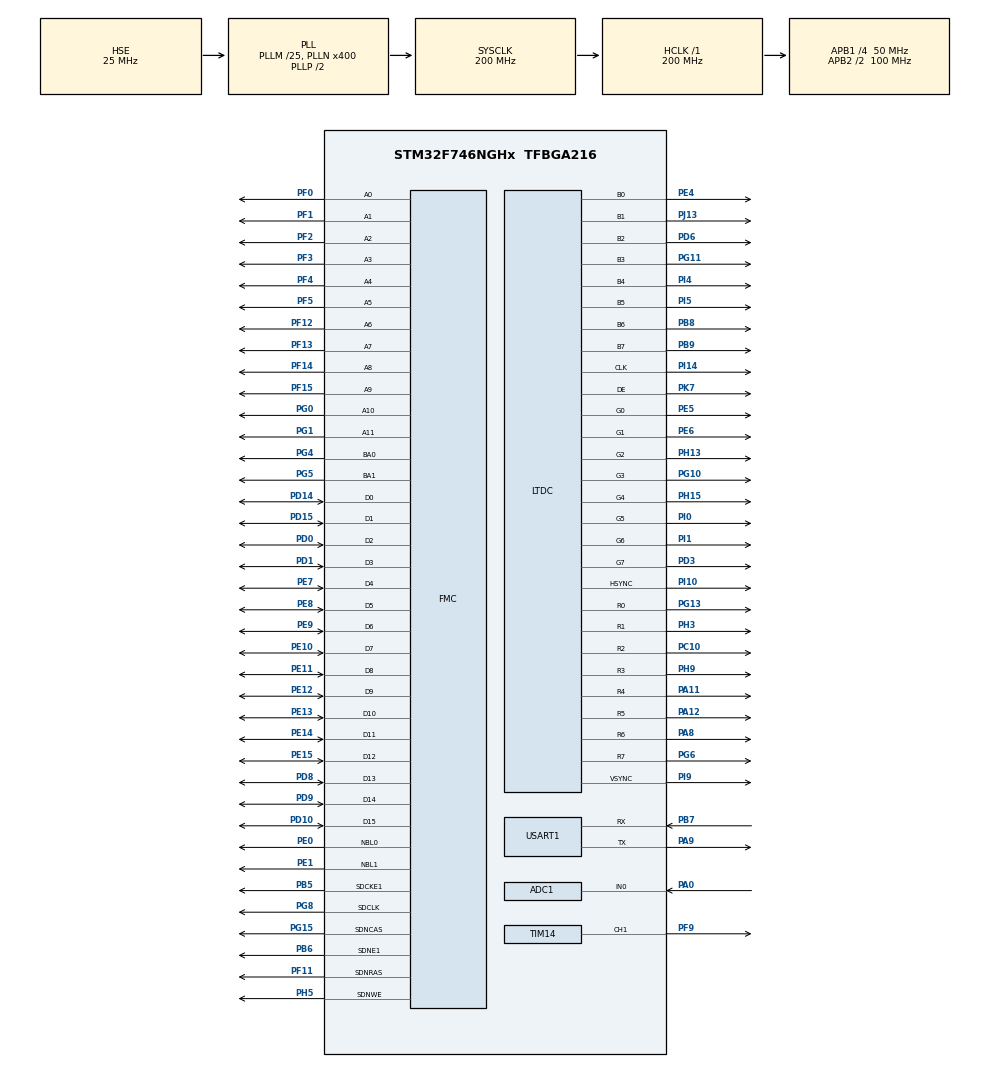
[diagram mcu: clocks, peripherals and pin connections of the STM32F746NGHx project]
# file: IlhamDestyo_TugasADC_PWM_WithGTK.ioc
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ADC1.Channel-1\#ChannelRegularConversion=ADC_CHANNEL_0
ADC1.ContinuousConvMode=ENABLE
ADC1.InjNumberOfConversion=0
ADC1.NbrOfConversionFlag=1
ADC1.Rank-1\#ChannelRegularConversion=1
ADC1.Resolution=ADC_RESOLUTION_12B
ADC1.SamplingTime-1\#ChannelRegularConversion=ADC_SAMPLETIME_144CYCLES
ADC1.master=1
CORTEX_M7.CPU_DCache=Enabled
CORTEX_M7.CPU_ICache=Enabled
FMC.WriteProtection1=FMC_SDRAM_WRITE_PROTECTION_DISABLE
FREERTOS.Tasks01=ADC_Task,3,128,StartADC,Default,NULL,Dynamic,NULL,NULL;PWM_Task,0,128,StartPWM,Default,NULL,Dynamic,NULL,NULL
FREERTOS.configUSE_NEWLIB_REENTRANT=1
LTDC.ActiveH=272
LTDC.ActiveW=480
Mcu.Family=STM32F7
Mcu.Name=STM32F746NGHx
Mcu.Package=TFBGA216
NVIC.LTDC_IRQn=true\:5\:0\:false\:false\:true\:true\:true\:true\:true
NVIC.PriorityGroup=NVIC_PRIORITYGROUP_4
NVIC.RCC_IRQn=true\:5\:0\:false\:false\:true\:true\:true\:false\:true
PA0/WKUP.Signal=ADCx_IN0
PA11.Mode=RGB888
PA11.Signal=LTDC_R4
PA12.Mode=RGB888
PA12.Signal=LTDC_R5
PA13.Mode=Serial_Wire
PA13.Signal=SYS_JTMS-SWDIO
PA14.Mode=Serial_Wire
PA14.Signal=SYS_JTCK-SWCLK
PA8.Mode=RGB888
PA8.Signal=LTDC_R6
PA9.Mode=Asynchronous
PA9.Signal=USART1_TX
PB5.Mode=SdramChipSelect2_1
PB5.Signal=FMC_SDCKE1
PB6.Mode=SdramChipSelect2_1
PB6.Signal=FMC_SDNE1
PB7.Mode=Asynchronous
PB7.Signal=USART1_RX
PB8.Mode=RGB888
PB8.Signal=LTDC_B6
PB9.Mode=RGB888
PB9.Signal=LTDC_B7
PC10.Mode=RGB888
PC10.Signal=LTDC_R2
PD0.Signal=FMC_D2_DA2
PD1.Signal=FMC_D3_DA3
PD10.Signal=FMC_D15_DA15
PD14.Signal=FMC_D0_DA0
PD15.Signal=FMC_D1_DA1
PD3.Mode=RGB888
PD3.Signal=LTDC_G7
PD6.Mode=RGB888
PD6.Signal=LTDC_B2
PD8.Signal=FMC_D13_DA13
PD9.Signal=FMC_D14_DA14
PE0.Signal=FMC_NBL0
PE1.Signal=FMC_NBL1
PE10.Signal=FMC_D7_DA7
PE11.Signal=FMC_D8_DA8
PE12.Signal=FMC_D9_DA9
PE13.Signal=FMC_D10_DA10
PE14.Signal=FMC_D11_DA11
PE15.Signal=FMC_D12_DA12
PE4.Mode=RGB888
PE4.Signal=LTDC_B0
PE5.Mode=RGB888
PE5.Signal=LTDC_G0
PE6.Mode=RGB888
PE6.Signal=LTDC_G1
PE7.Signal=FMC_D4_DA4
PE8.Signal=FMC_D5_DA5
PE9.Signal=FMC_D6_DA6
PF0.Signal=FMC_A0
PF1.Signal=FMC_A1
PF11.Signal=FMC_SDNRAS
PF12.Signal=FMC_A6
PF13.Signal=FMC_A7
PF14.Signal=FMC_A8
PF15.Signal=FMC_A9
PF2.Signal=FMC_A2
PF3.Signal=FMC_A3
PF4.Signal=FMC_A4
PF5.Signal=FMC_A5
PF9.Signal=S_TIM14_CH1
PG0.Signal=FMC_A10
PG1.Signal=FMC_A11
PG10.Mode=RGB888
PG10.Signal=LTDC_G3
PG11.Mode=RGB888
PG11.Signal=LTDC_B3
PG13.Mode=RGB888
PG13.Signal=LTDC_R0
PG15.Signal=FMC_SDNCAS
PG4.Signal=FMC_A14_BA0
PG5.Signal=FMC_A15_BA1
PG6.Mode=RGB888
PG6.Signal=LTDC_R7
PG8.Signal=FMC_SDCLK
PH0/OSC_IN.Mode=HSE-External-Oscillator
PH0/OSC_IN.Signal=RCC_OSC_IN
PH1/OSC_OUT.Mode=HSE-External-Oscillator
PH1/OSC_OUT.Signal=RCC_OSC_OUT
PH13.Mode=RGB888
PH13.Signal=LTDC_G2
PH15.Mode=RGB888
PH15.Signal=LTDC_G4
PH3.Mode=RGB888
PH3.Signal=LTDC_R1
PH5.Signal=FMC_SDNWE
PH9.Mode=RGB888
PH9.Signal=LTDC_R3
PI0.Mode=RGB888
PI0.Signal=LTDC_G5
PI1.Mode=RGB888
PI1.Signal=LTDC_G6
PI10.Mode=RGB888
PI10.Signal=LTDC_HSYNC
PI14.Mode=RGB888
PI14.Signal=LTDC_CLK
PI4.Mode=RGB888
PI4.Signal=LTDC_B4
PI5.Mode=RGB888
PI5.Signal=LTDC_B5
PI9.Mode=RGB888
PI9.Signal=LTDC_VSYNC
PJ13.Mode=RGB888
PJ13.Signal=LTDC_B1
PK7.Mode=RGB888
PK7.Signal=LTDC_DE
ProjectManager.HeapSize=0x200
ProjectManager.StackSize=0x400
ProjectManager.TargetToolchain=STM32CubeIDE
RCC.AHBFreq_Value=200000000
RCC.APB1CLKDivider=RCC_HCLK_DIV4
RCC.APB1Freq_Value=50000000
RCC.APB1TimFreq_Value=100000000
RCC.APB2CLKDivider=RCC_HCLK_DIV2
RCC.APB2Freq_Value=100000000
RCC.APB2TimFreq_Value=200000000
RCC.CortexFreq_Value=200000000
RCC.HCLKFreq_Value=200000000
RCC.HSE_VALUE=25000000
RCC.HSI_VALUE=16000000
RCC.LSE_VALUE=32768
RCC.PLL48CLockSelection=RCC_CLK48SOURCE_PLLSAIP
RCC.PLLI2SN=100
RCC.PLLM=25
RCC.PLLN=400
RCC.PLLQ=9
RCC.PLLSAIN=384
RCC.PLLSAIP=RCC_PLLSAIP_DIV8
RCC.PLLSAIR=5
RCC.PLLSAIRDiv=RCC_PLLSAIDIVR_8
RCC.PLLSourceVirtual=RCC_PLLSOURCE_HSE
RCC.SDMMCClockSelection=RCC_SDMMC1CLKSOURCE_CLK48
RCC.SYSCLKFreq_VALUE=200000000
RCC.SYSCLKSource=RCC_SYSCLKSOURCE_PLLCLK
RCC.USBFreq_Value=48000000
RCC.VCOOutputFreq_Value=400000000
SH.ADCx_IN0.0=ADC1_IN0,IN0
SH.FMC_A0.0=FMC_A0,12b-sda1
SH.FMC_A1.0=FMC_A1,12b-sda1
SH.FMC_A10.0=FMC_A10,12b-sda1
SH.FMC_A11.0=FMC_A11,12b-sda1
SH.FMC_A14_BA0.0=FMC_BA0,FourSdramBanks1
SH.FMC_A15_BA1.0=FMC_BA1,FourSdramBanks1
SH.FMC_A2.0=FMC_A2,12b-sda1
SH.FMC_A3.0=FMC_A3,12b-sda1
SH.FMC_A4.0=FMC_A4,12b-sda1
SH.FMC_A5.0=FMC_A5,12b-sda1
SH.FMC_A6.0=FMC_A6,12b-sda1
SH.FMC_A7.0=FMC_A7,12b-sda1
SH.FMC_A8.0=FMC_A8,12b-sda1
SH.FMC_A9.0=FMC_A9,12b-sda1
SH.FMC_D0_DA0.0=FMC_D0,sd-16b-d1
SH.FMC_D10_DA10.0=FMC_D10,sd-16b-d1
SH.FMC_D11_DA11.0=FMC_D11,sd-16b-d1
SH.FMC_D12_DA12.0=FMC_D12,sd-16b-d1
SH.FMC_D13_DA13.0=FMC_D13,sd-16b-d1
SH.FMC_D14_DA14.0=FMC_D14,sd-16b-d1
SH.FMC_D15_DA15.0=FMC_D15,sd-16b-d1
SH.FMC_D1_DA1.0=FMC_D1,sd-16b-d1
SH.FMC_D2_DA2.0=FMC_D2,sd-16b-d1
SH.FMC_D3_DA3.0=FMC_D3,sd-16b-d1
SH.FMC_D4_DA4.0=FMC_D4,sd-16b-d1
SH.FMC_D5_DA5.0=FMC_D5,sd-16b-d1
SH.FMC_D6_DA6.0=FMC_D6,sd-16b-d1
SH.FMC_D7_DA7.0=FMC_D7,sd-16b-d1
SH.FMC_D8_DA8.0=FMC_D8,sd-16b-d1
SH.FMC_D9_DA9.0=FMC_D9,sd-16b-d1
SH.FMC_NBL0.0=FMC_NBL0,Sd2ByteEnable1
SH.FMC_NBL1.0=FMC_NBL1,Sd2ByteEnable1
SH.FMC_SDCLK.0=FMC_SDCLK,12b-sda1
SH.FMC_SDNCAS.0=FMC_SDNCAS,12b-sda1
SH.FMC_SDNRAS.0=FMC_SDNRAS,12b-sda1
SH.FMC_SDNWE.0=FMC_SDNWE,12b-sda1
SH.S_TIM14_CH1.0=TIM14_CH1,PWM Generation1 CH1
TIM14.Channel=TIM_CHANNEL_1
TIM14.Period=1000
TIM14.Prescaler=840-1
USART1.VirtualMode-Asynchronous=VM_ASYNC
VP_CRC_VS_CRC.Mode=CRC_Activate
VP_DMA2D_VS_DMA2D.Mode=DMA2D_Activate
VP_FREERTOS_VS_CMSIS_V1.Mode=CMSIS_V1
VP_TIM14_VS_ClockSourceINT.Mode=Enable_Timer
board=STM32F746G-DISCO

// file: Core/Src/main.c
/* USER CODE BEGIN Header */
/**
  ******************************************************************************
  * @file           : main.c
  * @brief          : Main program body
  ******************************************************************************
  * @attention
  *
  * Copyright (c) 2022 STMicroelectronics.
  * All rights reserved.
  *
  * This software is licensed under terms that can be found in the LICENSE file
  * in the root directory of this software component.
  * If no LICENSE file comes with this software, it is provided AS-IS.
  *
  ******************************************************************************
  */
/* USER CODE END Header */
#include "main.h"
#include "cmsis_os.h"

/* USER CODE BEGIN Includes */
#include <stdio.h>
#include <stdlib.h>
#include <string.h>
#include <ctype.h>
/* USER CODE END Includes */

 ADC_HandleTypeDef hadc1;

CRC_HandleTypeDef hcrc;

DMA2D_HandleTypeDef hdma2d;

LTDC_HandleTypeDef hltdc;

TIM_HandleTypeDef htim14;

UART_HandleTypeDef huart1;

SDRAM_HandleTypeDef hsdram1;

osThreadId ADC_TaskHandle;
osThreadId PWM_TaskHandle;
/* USER CODE BEGIN PV */
int adcValue;
HAL_StatusTypeDef ret;
int PWM;
char *adc, *datapwm;
ADC_ChannelConfTypeDef sConfigPrivate = {0};

uint8_t Rx_data[64];
uint8_t Tx_data[64];
uint8_t buffer[64];
/* USER CODE END PV */

void SystemClock_Config(void);
static void MX_GPIO_Init(void);
static void MX_CRC_Init(void);
static void MX_DMA2D_Init(void);
static void MX_FMC_Init(void);
static void MX_LTDC_Init(void);
static void MX_USART1_UART_Init(void);
static void MX_ADC1_Init(void);
static void MX_TIM14_Init(void);
void StartADC(void const * argument);
void StartPWM(void const * argument);

/* USER CODE BEGIN PFP */
char *IntToStr(int x);
/* USER CODE END PFP */

int main(void)
{

  /* Enable I-Cache---------------------------------------------------------*/
  SCB_EnableICache();

  /* Enable D-Cache---------------------------------------------------------*/
  SCB_EnableDCache();

  /* MCU Configuration--------------------------------------------------------*/

  /* Reset of all peripherals, Initializes the Flash interface and the Systick. */
  HAL_Init();

  /* Configure the system clock */
  SystemClock_Config();

  /* Initialize all configured peripherals */
  MX_GPIO_Init();
  MX_CRC_Init();
  MX_DMA2D_Init();
  MX_FMC_Init();
  MX_LTDC_Init();
  MX_USART1_UART_Init();
  MX_ADC1_Init();
  MX_TIM14_Init();
  /* USER CODE BEGIN 2 */
  HAL_TIM_PWM_Start(&htim14, TIM_CHANNEL_1); // set enable start TIM4 CH 1

  BSP_SDRAM_Init(); /* Initializes the SDRAM device */
 __HAL_RCC_CRC_CLK_ENABLE(); /* Enable the CRC Module */
 //
 BSP_TS_Init(480, 272);

 BSP_LCD_Init();	// inisialisasi LCD
 BSP_LCD_LayerDefaultInit(LTDC_ACTIVE_LAYER, LCD_FB_START_ADDRESS); // inisialisasi layer
 BSP_LCD_SelectLayer(LTDC_ACTIVE_LAYER); // set layer

 BSP_LCD_Clear(LCD_COLOR_DARKGREEN); // set clear lcd color black
 BSP_LCD_SetFont(&LCD_DEFAULT_FONT); // set font lcd
 BSP_LCD_SetTextColor(LCD_COLOR_BROWN);
  /* USER CODE END 2 */

  /* Create the thread(s) */
  /* definition and creation of ADC_Task */
  osThreadDef(ADC_Task, StartADC, osPriorityRealtime, 0, 128);
  ADC_TaskHandle = osThreadCreate(osThread(ADC_Task), NULL);

  /* definition and creation of PWM_Task */
  osThreadDef(PWM_Task, StartPWM, osPriorityNormal, 0, 128);
  PWM_TaskHandle = osThreadCreate(osThread(PWM_Task), NULL);

  /* Start scheduler */
  osKernelStart();

  /* We should never get here as control is now taken by the scheduler */
  /* Infinite loop */
  while (1)
  {

  }
}

void SystemClock_Config(void)
{
  RCC_OscInitTypeDef RCC_OscInitStruct = {0};
  RCC_ClkInitTypeDef RCC_ClkInitStruct = {0};

  /** Configure the main internal regulator output voltage
  */
  __HAL_RCC_PWR_CLK_ENABLE();
  __HAL_PWR_VOLTAGESCALING_CONFIG(PWR_REGULATOR_VOLTAGE_SCALE1);

  /** Initializes the RCC Oscillators according to the specified parameters
  * in the RCC_OscInitTypeDef structure.
  */
  RCC_OscInitStruct.OscillatorType = RCC_OSCILLATORTYPE_HSE;
  RCC_OscInitStruct.HSEState = RCC_HSE_ON;
  RCC_OscInitStruct.PLL.PLLState = RCC_PLL_ON;
  RCC_OscInitStruct.PLL.PLLSource = RCC_PLLSOURCE_HSE;
  RCC_OscInitStruct.PLL.PLLM = 25;
  RCC_OscInitStruct.PLL.PLLN = 400;
  RCC_OscInitStruct.PLL.PLLP = RCC_PLLP_DIV2;
  RCC_OscInitStruct.PLL.PLLQ = 9;
  if (HAL_RCC_OscConfig(&RCC_OscInitStruct) != HAL_OK)
  {
    Error_Handler();
  }

  /** Activate the Over-Drive mode
  */
  if (HAL_PWREx_EnableOverDrive() != HAL_OK)
  {
    Error_Handler();
  }

  /** Initializes the CPU, AHB and APB buses clocks
  */
  RCC_ClkInitStruct.ClockType = RCC_CLOCKTYPE_HCLK|RCC_CLOCKTYPE_SYSCLK
                              |RCC_CLOCKTYPE_PCLK1|RCC_CLOCKTYPE_PCLK2;
  RCC_ClkInitStruct.SYSCLKSource = RCC_SYSCLKSOURCE_PLLCLK;
  RCC_ClkInitStruct.AHBCLKDivider = RCC_SYSCLK_DIV1;
  RCC_ClkInitStruct.APB1CLKDivider = RCC_HCLK_DIV4;
  RCC_ClkInitStruct.APB2CLKDivider = RCC_HCLK_DIV2;

  if (HAL_RCC_ClockConfig(&RCC_ClkInitStruct, FLASH_LATENCY_6) != HAL_OK)
  {
    Error_Handler();
  }
}

static void MX_ADC1_Init(void)
{

  ADC_ChannelConfTypeDef sConfig = {0};

  /** Configure the global features of the ADC (Clock, Resolution, Data Alignment and number of conversion)
  */
  hadc1.Instance = ADC1;
  hadc1.Init.ClockPrescaler = ADC_CLOCK_SYNC_PCLK_DIV4;
  hadc1.Init.Resolution = ADC_RESOLUTION_12B;
  hadc1.Init.ScanConvMode = ADC_SCAN_DISABLE;
  hadc1.Init.ContinuousConvMode = ENABLE;
  hadc1.Init.DiscontinuousConvMode = DISABLE;
  hadc1.Init.ExternalTrigConvEdge = ADC_EXTERNALTRIGCONVEDGE_NONE;
  hadc1.Init.ExternalTrigConv = ADC_SOFTWARE_START;
  hadc1.Init.DataAlign = ADC_DATAALIGN_RIGHT;
  hadc1.Init.NbrOfConversion = 1;
  hadc1.Init.DMAContinuousRequests = DISABLE;
  hadc1.Init.EOCSelection = ADC_EOC_SINGLE_CONV;
  if (HAL_ADC_Init(&hadc1) != HAL_OK)
  {
    Error_Handler();
  }

  /** Configure for the selected ADC regular channel its corresponding rank in the sequencer and its sample time.
  */
  sConfig.Channel = ADC_CHANNEL_0;
  sConfig.Rank = ADC_REGULAR_RANK_1;
  sConfig.SamplingTime = ADC_SAMPLETIME_144CYCLES;
  if (HAL_ADC_ConfigChannel(&hadc1, &sConfig) != HAL_OK)
  {
    Error_Handler();
  }

}

static void MX_CRC_Init(void)
{

  hcrc.Instance = CRC;
  hcrc.Init.DefaultPolynomialUse = DEFAULT_POLYNOMIAL_ENABLE;
  hcrc.Init.DefaultInitValueUse = DEFAULT_INIT_VALUE_ENABLE;
  hcrc.Init.InputDataInversionMode = CRC_INPUTDATA_INVERSION_NONE;
  hcrc.Init.OutputDataInversionMode = CRC_OUTPUTDATA_INVERSION_DISABLE;
  hcrc.InputDataFormat = CRC_INPUTDATA_FORMAT_BYTES;
  if (HAL_CRC_Init(&hcrc) != HAL_OK)
  {
    Error_Handler();
  }

}

static void MX_DMA2D_Init(void)
{

  hdma2d.Instance = DMA2D;
  hdma2d.Init.Mode = DMA2D_M2M;
  hdma2d.Init.ColorMode = DMA2D_OUTPUT_ARGB8888;
  hdma2d.Init.OutputOffset = 0;
  hdma2d.LayerCfg[1].InputOffset = 0;
  hdma2d.LayerCfg[1].InputColorMode = DMA2D_INPUT_ARGB8888;
  hdma2d.LayerCfg[1].AlphaMode = DMA2D_NO_MODIF_ALPHA;
  hdma2d.LayerCfg[1].InputAlpha = 0;
  if (HAL_DMA2D_Init(&hdma2d) != HAL_OK)
  {
    Error_Handler();
  }
  if (HAL_DMA2D_ConfigLayer(&hdma2d, 1) != HAL_OK)
  {
    Error_Handler();
  }

}

static void MX_LTDC_Init(void)
{

  LTDC_LayerCfgTypeDef pLayerCfg = {0};
  LTDC_LayerCfgTypeDef pLayerCfg1 = {0};

  hltdc.Instance = LTDC;
  hltdc.Init.HSPolarity = LTDC_HSPOLARITY_AL;
  hltdc.Init.VSPolarity = LTDC_VSPOLARITY_AL;
  hltdc.Init.DEPolarity = LTDC_DEPOLARITY_AL;
  hltdc.Init.PCPolarity = LTDC_PCPOLARITY_IPC;
  hltdc.Init.HorizontalSync = 7;
  hltdc.Init.VerticalSync = 3;
  hltdc.Init.AccumulatedHBP = 14;
  hltdc.Init.AccumulatedVBP = 5;
  hltdc.Init.AccumulatedActiveW = 494;
  hltdc.Init.AccumulatedActiveH = 277;
  hltdc.Init.TotalWidth = 500;
  hltdc.Init.TotalHeigh = 279;
  hltdc.Init.Backcolor.Blue = 0;
  hltdc.Init.Backcolor.Green = 0;
  hltdc.Init.Backcolor.Red = 0;
  if (HAL_LTDC_Init(&hltdc) != HAL_OK)
  {
    Error_Handler();
  }
  pLayerCfg.WindowX0 = 0;
  pLayerCfg.WindowX1 = 0;
  pLayerCfg.WindowY0 = 0;
  pLayerCfg.WindowY1 = 0;
  pLayerCfg.PixelFormat = LTDC_PIXEL_FORMAT_ARGB8888;
  pLayerCfg.Alpha = 0;
  pLayerCfg.Alpha0 = 0;
  pLayerCfg.BlendingFactor1 = LTDC_BLENDING_FACTOR1_CA;
  pLayerCfg.BlendingFactor2 = LTDC_BLENDING_FACTOR2_CA;
  pLayerCfg.FBStartAdress = 0;
  pLayerCfg.ImageWidth = 0;
  pLayerCfg.ImageHeight = 0;
  pLayerCfg.Backcolor.Blue = 0;
  pLayerCfg.Backcolor.Green = 0;
  pLayerCfg.Backcolor.Red = 0;
  if (HAL_LTDC_ConfigLayer(&hltdc, &pLayerCfg, 0) != HAL_OK)
  {
    Error_Handler();
  }
  pLayerCfg1.WindowX0 = 0;
  pLayerCfg1.WindowX1 = 0;
  pLayerCfg1.WindowY0 = 0;
  pLayerCfg1.WindowY1 = 0;
  pLayerCfg1.PixelFormat = LTDC_PIXEL_FORMAT_ARGB8888;
  pLayerCfg1.Alpha = 0;
  pLayerCfg1.Alpha0 = 0;
  pLayerCfg1.BlendingFactor1 = LTDC_BLENDING_FACTOR1_CA;
  pLayerCfg1.BlendingFactor2 = LTDC_BLENDING_FACTOR2_CA;
  pLayerCfg1.FBStartAdress = 0;
  pLayerCfg1.ImageWidth = 0;
  pLayerCfg1.ImageHeight = 0;
  pLayerCfg1.Backcolor.Blue = 0;
  pLayerCfg1.Backcolor.Green = 0;
  pLayerCfg1.Backcolor.Red = 0;
  if (HAL_LTDC_ConfigLayer(&hltdc, &pLayerCfg1, 1) != HAL_OK)
  {
    Error_Handler();
  }

}

static void MX_TIM14_Init(void)
{

  TIM_OC_InitTypeDef sConfigOC = {0};

  htim14.Instance = TIM14;
  htim14.Init.Prescaler = 840-1;
  htim14.Init.CounterMode = TIM_COUNTERMODE_UP;
  htim14.Init.Period = 1000;
  htim14.Init.ClockDivision = TIM_CLOCKDIVISION_DIV1;
  htim14.Init.AutoReloadPreload = TIM_AUTORELOAD_PRELOAD_DISABLE;
  if (HAL_TIM_Base_Init(&htim14) != HAL_OK)
  {
    Error_Handler();
  }
  if (HAL_TIM_PWM_Init(&htim14) != HAL_OK)
  {
    Error_Handler();
  }
  sConfigOC.OCMode = TIM_OCMODE_PWM1;
  sConfigOC.Pulse = 0;
  sConfigOC.OCPolarity = TIM_OCPOLARITY_HIGH;
  sConfigOC.OCFastMode = TIM_OCFAST_DISABLE;
  if (HAL_TIM_PWM_ConfigChannel(&htim14, &sConfigOC, TIM_CHANNEL_1) != HAL_OK)
  {
    Error_Handler();
  }
  HAL_TIM_MspPostInit(&htim14);

}

static void MX_USART1_UART_Init(void)
{

  huart1.Instance = USART1;
  huart1.Init.BaudRate = 115200;
  huart1.Init.WordLength = UART_WORDLENGTH_8B;
  huart1.Init.StopBits = UART_STOPBITS_1;
  huart1.Init.Parity = UART_PARITY_NONE;
  huart1.Init.Mode = UART_MODE_TX_RX;
  huart1.Init.HwFlowCtl = UART_HWCONTROL_NONE;
  huart1.Init.OverSampling = UART_OVERSAMPLING_16;
  huart1.Init.OneBitSampling = UART_ONE_BIT_SAMPLE_DISABLE;
  huart1.AdvancedInit.AdvFeatureInit = UART_ADVFEATURE_NO_INIT;
  if (HAL_UART_Init(&huart1) != HAL_OK)
  {
    Error_Handler();
  }

}

/* FMC initialization function */
static void MX_FMC_Init(void)
{

  FMC_SDRAM_TimingTypeDef SdramTiming = {0};

  /** Perform the SDRAM1 memory initialization sequence
  */
  hsdram1.Instance = FMC_SDRAM_DEVICE;
  /* hsdram1.Init */
  hsdram1.Init.SDBank = FMC_SDRAM_BANK2;
  hsdram1.Init.ColumnBitsNumber = FMC_SDRAM_COLUMN_BITS_NUM_8;
  hsdram1.Init.RowBitsNumber = FMC_SDRAM_ROW_BITS_NUM_12;
  hsdram1.Init.MemoryDataWidth = FMC_SDRAM_MEM_BUS_WIDTH_16;
  hsdram1.Init.InternalBankNumber = FMC_SDRAM_INTERN_BANKS_NUM_4;
  hsdram1.Init.CASLatency = FMC_SDRAM_CAS_LATENCY_1;
  hsdram1.Init.WriteProtection = FMC_SDRAM_WRITE_PROTECTION_DISABLE;
  hsdram1.Init.SDClockPeriod = FMC_SDRAM_CLOCK_DISABLE;
  hsdram1.Init.ReadBurst = FMC_SDRAM_RBURST_DISABLE;
  hsdram1.Init.ReadPipeDelay = FMC_SDRAM_RPIPE_DELAY_0;
  /* SdramTiming */
  SdramTiming.LoadToActiveDelay = 16;
  SdramTiming.ExitSelfRefreshDelay = 16;
  SdramTiming.SelfRefreshTime = 16;
  SdramTiming.RowCycleDelay = 16;
  SdramTiming.WriteRecoveryTime = 16;
  SdramTiming.RPDelay = 16;
  SdramTiming.RCDDelay = 16;

  if (HAL_SDRAM_Init(&hsdram1, &SdramTiming) != HAL_OK)
  {
    Error_Handler( );
  }

}

static void MX_GPIO_Init(void)
{

  /* GPIO Ports Clock Enable */
  __HAL_RCC_GPIOE_CLK_ENABLE();
  __HAL_RCC_GPIOB_CLK_ENABLE();
  __HAL_RCC_GPIOA_CLK_ENABLE();
  __HAL_RCC_GPIOG_CLK_ENABLE();
  __HAL_RCC_GPIOJ_CLK_ENABLE();
  __HAL_RCC_GPIOD_CLK_ENABLE();
  __HAL_RCC_GPIOC_CLK_ENABLE();
  __HAL_RCC_GPIOI_CLK_ENABLE();
  __HAL_RCC_GPIOK_CLK_ENABLE();
  __HAL_RCC_GPIOF_CLK_ENABLE();
  __HAL_RCC_GPIOH_CLK_ENABLE();

}

/* USER CODE BEGIN 4 */
// Mengkonvert dari Integer ke String
char *IntToStr(int x){
	char *str=(char *)malloc(10 * sizeof (char));	// Mengalokasikan blok memory sebesar 10byte dan di pointing ke pointer str
	sprintf(str, "%d", x);	// Memasukkan data integer x ke str
	return str;
}

/* USER CODE BEGIN Header_StartADC */
/**
  * @brief  Function implementing the ADC_Task thread.
  * @param  argument: Not used
  * @retval None
  */
/* USER CODE END Header_StartADC */
void StartADC(void const * argument)
{
  /* USER CODE BEGIN 5 */
	ret = HAL_ADC_Start(&hadc1);
	if(ret != HAL_OK){
		Error_Handler();
	}

	ret = HAL_ADC_PollForConversion(&hadc1, 20);
	if(ret != HAL_OK){
		Error_Handler();
	}

	HAL_Delay(100);

  /* Infinite loop */
  for(;;)
  {
	  sConfigPrivate.Rank = ADC_REGULAR_RANK_1;	//set ADC regular conversion rank 1
	  sConfigPrivate.Channel = ADC_CHANNEL_0;	//set ADC Channel 0
	  HAL_ADC_ConfigChannel(&hadc1, &sConfigPrivate);	//set configurations adc1 rank and channel configiration structur
	  HAL_ADC_Start(&hadc1);//Start ADC Enable
	  HAL_ADC_PollForConversion(&hadc1,1000);
	  adcValue = HAL_ADC_GetValue(&hadc1);//read ADC Value
	  adc = IntToStr(adcValue); //ADC convertion from integer to string
	  strcpy(Tx_data , adc);	// Copy ADC string to Tx_Data
	  HAL_ADC_Stop(&hadc1);	// Stop and Disable ADC
	  //transmit data uart from ADC
	  HAL_UART_Transmit(&huart1, (uint8_t *)Tx_data, sizeof(Tx_data), 1000);

    osDelay(500);	// delay 500ms
  }
  /* USER CODE END 5 */
}

/* USER CODE BEGIN Header_StartPWM */
/**
* @brief Function implementing the PWM_Task thread.
* @param argument: Not used
* @retval None
*/
/* USER CODE END Header_StartPWM */
void StartPWM(void const * argument)
{
  /* USER CODE BEGIN StartPWM */
  /* Infinite loop */
  for(;;)
  {
	  // Receive data from uart
	  HAL_UART_Receive(&huart1, (uint8_t *)&Rx_data, sizeof(Rx_data), 1000);
	  memset(buffer, '\0', 64);	// set clear buffer
	  memcpy(buffer, Rx_data, 64);	// copy data to buffer

	  if(buffer[0]=='0' && buffer[1]=='\0'){ // jika buffer = 0
		  PWM = 1; // set value PWM = 1 to duty cycle 1%
	  }
	  else if(buffer[0]=='1' && buffer[1]=='0' && buffer[2]=='\0'){ // jika buffer = 10
		  PWM = 100; // set value PWM = 100 to duty cycle 10%
	  }
	  else if(buffer[0]=='2' && buffer[1]=='0' && buffer[2]=='\0'){ // jika buffer = 20
		  PWM = 200; // set value PWM = 200 to duty cycle 20%
	  }
	  else if(buffer[0]=='3' && buffer[1]=='0' && buffer[2]=='\0'){ // jika buffer = 30
		  PWM = 300; // set value PWM = 300 to duty cycle 30%
	  }
	  else if(buffer[0]=='4' && buffer[1]=='0' && buffer[2]=='\0'){ // jika buffer = 40
		  PWM = 400; // set value PWM = 400 to duty cycle 40%
	  }
	  else if(buffer[0]=='5' && buffer[1]=='0' && buffer[2]=='\0'){ // jika buffer = 50
		  PWM = 500; // set value PWM = 500 to duty cycle 50%
	  }
	  else if(buffer[0]=='6' && buffer[1]=='0' && buffer[2]=='\0'){ // jika buffer = 60
		  PWM = 600; // set value PWM = 600 to duty cycle 60%
	  }
	  else if(buffer[0]=='7' && buffer[1]=='0' && buffer[2]=='\0'){ // jika buffer = 70
		  PWM = 700; // set value PWM = 700 to duty cycle 70%
	  }
	  else if(buffer[0]=='8' && buffer[1]=='0' && buffer[2]=='\0'){ // jika buffer = 80
		  PWM = 800; // set value PWM = 800 to duty cycle 80%
	  }
	  else if(buffer[0]=='9' && buffer[1]=='0' && buffer[2]=='\0'){ // jika buffer = 90
		  PWM = 900; // set value PWM = 90 to duty cycle 90%
	  }
	  else if(buffer[0]=='1' && buffer[1]=='0' && buffer[2]=='0' && buffer[3]=='\0'){ // jika buffer = 100
		  PWM = 1000; // set value PWM = 1000 to duty cycle 100%
	  }

	  __HAL_TIM_SET_COMPARE(&htim14,TIM_CHANNEL_1, PWM);	//set compare TIM dengan PWM
    osDelay(1); // delay 1ms
    memset(Rx_data, '\0', 64);	// set clear Rx_data
  }
  /* USER CODE END StartPWM */
}

/* USER CODE END 4 */
void Error_Handler(void)
{
  __disable_irq();
  while (1)
  {
  }
}
